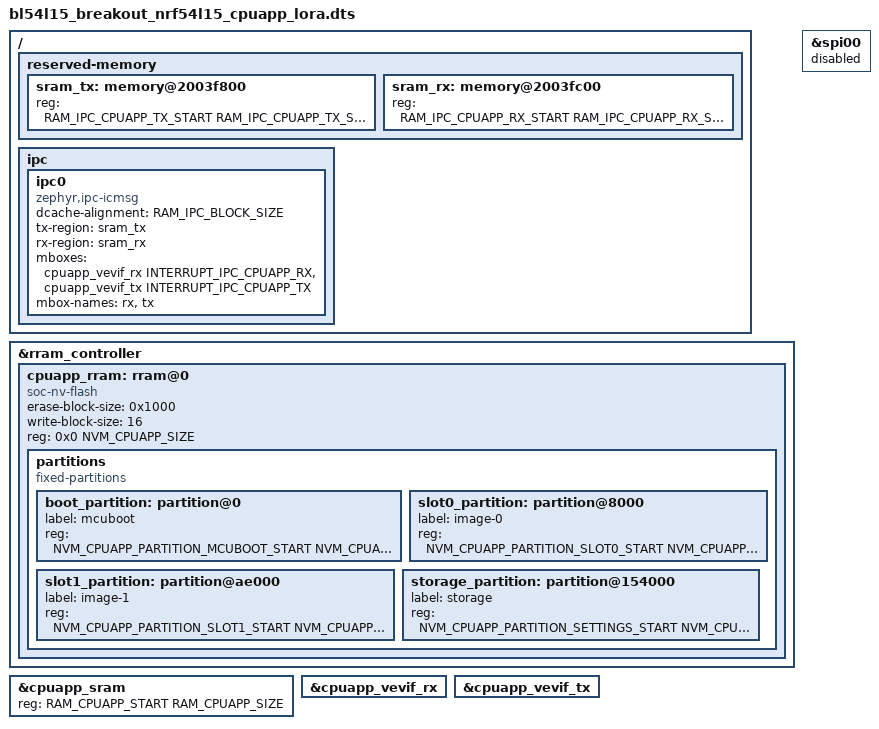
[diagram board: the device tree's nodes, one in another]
/*
 * Copyright (c) 2025 Jamie M.
 *
 * All right reserved. This code is NOT apache or FOSS/copyleft licensed.
 */

#include "bl54l15_breakout_nrf54l15_cpuapp.dts"
#include "bl54l15_breakout_lora_common.dtsi"

/delete-node/ &boot_partition;
/delete-node/ &slot0_partition;
/delete-node/ &slot1_partition;
/delete-node/ &storage_partition;
/delete-node/ &cpuapp_rram;

/ {
	reserved-memory {
		#address-cells = <1>;
		#size-cells = <1>;
		ranges;

		sram_tx: memory@2003f800 {
			reg = <RAM_IPC_CPUAPP_TX_START RAM_IPC_CPUAPP_TX_SIZE>;
		};

		sram_rx: memory@2003fc00 {
			reg = <RAM_IPC_CPUAPP_RX_START RAM_IPC_CPUAPP_RX_SIZE>;
		};
	};

	ipc {
		ipc0: ipc0 {
			compatible = "zephyr,ipc-icmsg";
			dcache-alignment = <RAM_IPC_BLOCK_SIZE>;
			tx-region = <&sram_tx>;
			rx-region = <&sram_rx>;
			mboxes = <&cpuapp_vevif_rx INTERRUPT_IPC_CPUAPP_RX>, <&cpuapp_vevif_tx INTERRUPT_IPC_CPUAPP_TX>;
			mbox-names = "rx", "tx";
			status = "okay";
		};
	};
};

&rram_controller {
	cpuapp_rram: rram@0 {
		compatible = "soc-nv-flash";
		erase-block-size = <0x1000>;
		write-block-size = <16>;
		reg = <0x0 NVM_CPUAPP_SIZE>;

		partitions {
			compatible = "fixed-partitions";
			#address-cells = <1>;
			#size-cells = <1>;

			boot_partition: partition@0 {
				label = "mcuboot";
				reg = <NVM_CPUAPP_PARTITION_MCUBOOT_START NVM_CPUAPP_PARTITION_MCUBOOT_SIZE>;
			};

			slot0_partition: partition@8000 {
				label = "image-0";
				reg = <NVM_CPUAPP_PARTITION_SLOT0_START NVM_CPUAPP_PARTITION_SLOT0_SIZE>;
			};

			slot1_partition: partition@ae000 {
				label = "image-1";
				reg = <NVM_CPUAPP_PARTITION_SLOT1_START NVM_CPUAPP_PARTITION_SLOT1_SIZE>;
			};

			storage_partition: partition@154000 {
				label = "storage";
				reg = <NVM_CPUAPP_PARTITION_SETTINGS_START NVM_CPUAPP_PARTITION_SETTINGS_SIZE>;
			};
		};
	};
};

&cpuapp_sram {
	reg = <RAM_CPUAPP_START RAM_CPUAPP_SIZE>;
	ranges = <0x0 RAM_CPUAPP_START RAM_CPUAPP_SIZE>;
};

&cpuapp_vevif_rx {
	status = "okay";
};

&cpuapp_vevif_tx {
	status = "okay";
};

&spi00 {
	status = "disabled";
};
